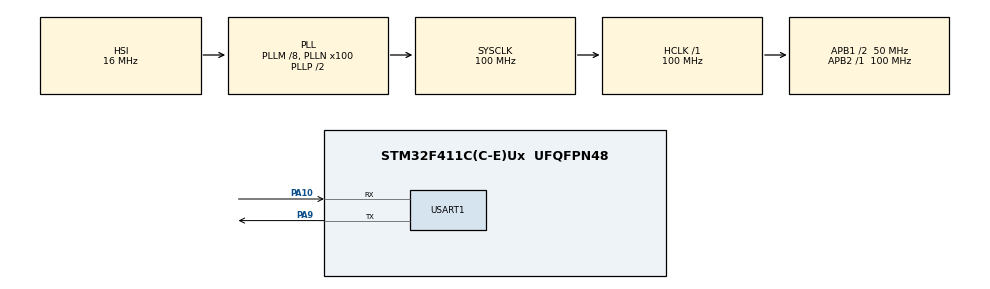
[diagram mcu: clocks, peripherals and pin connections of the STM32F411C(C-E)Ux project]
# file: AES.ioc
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Mcu.Family=STM32F4
Mcu.Name=STM32F411C(C-E)Ux
Mcu.Package=UFQFPN48
NVIC.PriorityGroup=NVIC_PRIORITYGROUP_4
PA10.Mode=Asynchronous
PA10.Signal=USART1_RX
PA13.Mode=Serial_Wire
PA13.Signal=SYS_JTMS-SWDIO
PA14.Mode=Serial_Wire
PA14.Signal=SYS_JTCK-SWCLK
PA9.Mode=Asynchronous
PA9.Signal=USART1_TX
PC14-OSC32_IN.Mode=LSE-External-Oscillator
PC14-OSC32_IN.Signal=RCC_OSC32_IN
PC15-OSC32_OUT.Mode=LSE-External-Oscillator
PC15-OSC32_OUT.Signal=RCC_OSC32_OUT
PH0\ -\ OSC_IN.Mode=HSE-External-Oscillator
PH0\ -\ OSC_IN.Signal=RCC_OSC_IN
PH1\ -\ OSC_OUT.Mode=HSE-External-Oscillator
PH1\ -\ OSC_OUT.Signal=RCC_OSC_OUT
ProjectManager.HeapSize=0x200
ProjectManager.StackSize=0x400
ProjectManager.TargetToolchain=MDK-ARM V5.32
RCC.48MHZClocksFreq_Value=50000000
RCC.AHBFreq_Value=100000000
RCC.APB1CLKDivider=RCC_HCLK_DIV2
RCC.APB1Freq_Value=50000000
RCC.APB1TimFreq_Value=100000000
RCC.APB2Freq_Value=100000000
RCC.APB2TimFreq_Value=100000000
RCC.CortexFreq_Value=100000000
RCC.HCLKFreq_Value=100000000
RCC.HSE_VALUE=25000000
RCC.HSI_VALUE=16000000
RCC.PLLM=8
RCC.PLLN=100
RCC.SYSCLKFreq_VALUE=100000000
RCC.SYSCLKSource=RCC_SYSCLKSOURCE_PLLCLK
RCC.VCOOutputFreq_Value=200000000
USART1.VirtualMode=VM_ASYNC
board=custom

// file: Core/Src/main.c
/* USER CODE BEGIN Header */
/**
  ******************************************************************************
  * @file           : main.c
  * @brief          : Main program body
  ******************************************************************************
  * @attention
  *
  * Copyright (c) 2026 STMicroelectronics.
  * All rights reserved.
  *
  * This software is licensed under terms that can be found in the LICENSE file
  * in the root directory of this software component.
  * If no LICENSE file comes with this software, it is provided AS-IS.
  *
  ******************************************************************************
  */
/* USER CODE END Header */
#include "main.h"
#include "usart.h"
#include "gpio.h"

/* USER CODE BEGIN Includes */
#include <string.h>
#include "aes.h"
/* USER CODE END Includes */

void SystemClock_Config(void);
/* USER CODE BEGIN PFP */
void print_str(const char *pStr);
void print_hex(const uint8_t *pData, size_t nLength);
/* USER CODE END PFP */

int main(void)
{

  /* MCU Configuration--------------------------------------------------------*/

  /* Reset of all peripherals, Initializes the Flash interface and the Systick. */
  HAL_Init();

  /* Configure the system clock */
  SystemClock_Config();

  /* Initialize all configured peripherals */
  MX_GPIO_Init();
  MX_USART1_UART_Init();
  /* USER CODE BEGIN 2 */

  {
    /* 明文放在 16 字节的缓冲区里。数组先整体清零，再拷字符串进去——
       "Eternal-Chip" 只占 12 个字符，剩下 3 个字节如果不清零就是栈上的
       随机值，算出来的密文每次都不一样，没法拿去和在线工具比对。 */
    uint8_t buf[16]        = {0};
    uint8_t saveBuf[16]    = {0};   /* 存放加密结果 */
    uint8_t decryptBuf[17] = {0};   /* 存放解密结果，多留 1 个字节保证末尾是 '\0' */

    /* 密钥和初值都是 16 字节，正好 128 位，所以结尾不带 '\0' */
    const unsigned char AES128key[16] = "123456789abcdefa";
    const unsigned char AES_IV[16]    = "0102030405123456";

    memcpy(buf, "Eternal-Chip", 13);          /* 12 个字符 + 结尾的 '\0' */

    AES_Init(AES128key);                      /* 先用密钥做扩展，之后才能加解密 */

    AES_Encrypt(buf, saveBuf, sizeof(buf), AES_IV);
    print_str("aes_encrypt = ");
    print_hex(saveBuf, sizeof(saveBuf));

    AES_Decrypt(saveBuf, decryptBuf, sizeof(saveBuf), AES_IV);
    print_str("decryptBuf  = [");
    print_str((char *)decryptBuf);
    print_str("]\r\n");
  }

  /* USER CODE END 2 */

  /* Infinite loop */
  while (1)
  {

  }
}

void SystemClock_Config(void)
{
  RCC_OscInitTypeDef RCC_OscInitStruct = {0};
  RCC_ClkInitTypeDef RCC_ClkInitStruct = {0};

  /** Configure the main internal regulator output voltage
  */
  __HAL_RCC_PWR_CLK_ENABLE();
  __HAL_PWR_VOLTAGESCALING_CONFIG(PWR_REGULATOR_VOLTAGE_SCALE1);

  /** Initializes the RCC Oscillators according to the specified parameters
  * in the RCC_OscInitTypeDef structure.
  */
  RCC_OscInitStruct.OscillatorType = RCC_OSCILLATORTYPE_HSI;
  RCC_OscInitStruct.HSIState = RCC_HSI_ON;
  RCC_OscInitStruct.HSICalibrationValue = RCC_HSICALIBRATION_DEFAULT;
  RCC_OscInitStruct.PLL.PLLState = RCC_PLL_ON;
  RCC_OscInitStruct.PLL.PLLSource = RCC_PLLSOURCE_HSI;
  RCC_OscInitStruct.PLL.PLLM = 8;
  RCC_OscInitStruct.PLL.PLLN = 100;
  RCC_OscInitStruct.PLL.PLLP = RCC_PLLP_DIV2;
  RCC_OscInitStruct.PLL.PLLQ = 4;
  if (HAL_RCC_OscConfig(&RCC_OscInitStruct) != HAL_OK)
  {
    Error_Handler();
  }

  /** Initializes the CPU, AHB and APB buses clocks
  */
  RCC_ClkInitStruct.ClockType = RCC_CLOCKTYPE_HCLK|RCC_CLOCKTYPE_SYSCLK
                              |RCC_CLOCKTYPE_PCLK1|RCC_CLOCKTYPE_PCLK2;
  RCC_ClkInitStruct.SYSCLKSource = RCC_SYSCLKSOURCE_PLLCLK;
  RCC_ClkInitStruct.AHBCLKDivider = RCC_SYSCLK_DIV1;
  RCC_ClkInitStruct.APB1CLKDivider = RCC_HCLK_DIV2;
  RCC_ClkInitStruct.APB2CLKDivider = RCC_HCLK_DIV1;

  if (HAL_RCC_ClockConfig(&RCC_ClkInitStruct, FLASH_LATENCY_3) != HAL_OK)
  {
    Error_Handler();
  }
}

/* USER CODE BEGIN 4 */

/**
  * @brief  向串口 1 发送一个以 '\0' 结尾的字符串
  * @param  pStr 要发送的字符串
  */
void print_str(const char *pStr)
{
  HAL_UART_Transmit(&huart1, (uint8_t *)pStr, (uint16_t)strlen(pStr), HAL_MAX_DELAY);
}

/**
  * @brief  把一段数据按十六进制打印到串口 1，末尾换行
  *
  * 加解密出来的都是不可打印字节，直接按字符串发出去在串口助手上
  * 只会看到一团乱码，所以统一转成十六进制显示。
  *
  * @param  pData   要打印的数据
  * @param  nLength 数据长度（字节）
  */
void print_hex(const uint8_t *pData, size_t nLength)
{
  static const char szHex[] = "0123456789abcdef";
  uint8_t chLine[3];
  size_t  i;

  for (i = 0; i < nLength; i++)
  {
    chLine[0] = (uint8_t)szHex[(pData[i] >> 4) & 0x0F];
    chLine[1] = (uint8_t)szHex[pData[i] & 0x0F];
    chLine[2] = ' ';
    HAL_UART_Transmit(&huart1, chLine, 3, HAL_MAX_DELAY);
  }

  HAL_UART_Transmit(&huart1, (uint8_t *)"\r\n", 2, HAL_MAX_DELAY);
}

/* USER CODE END 4 */

void Error_Handler(void)
{
  __disable_irq();
  while (1)
  {
  }
}
